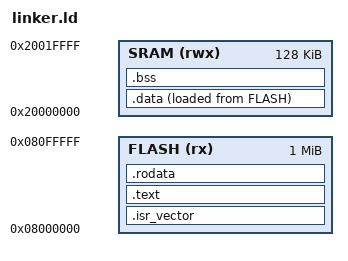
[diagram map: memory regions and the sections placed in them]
/* Linker script for STM32F407VG */
/* 1 MB Flash, 192 KB SRAM (128K main + 64K CCM) */

MEMORY
{
    FLASH (rx)  : ORIGIN = 0x08000000, LENGTH = 1024K
    SRAM  (rwx) : ORIGIN = 0x20000000, LENGTH = 128K
}

_stack_top = ORIGIN(SRAM) + LENGTH(SRAM);

SECTIONS
{
    .isr_vector :
    {
        . = ALIGN(4);
        KEEP(*(.isr_vector))
        . = ALIGN(4);
    } > FLASH

    .text :
    {
        . = ALIGN(4);
        *(.text)
        *(.text*)
        . = ALIGN(4);
    } > FLASH

    .rodata :
    {
        . = ALIGN(4);
        *(.rodata)
        *(.rodata*)
        . = ALIGN(4);
    } > FLASH

    _sidata = LOADADDR(.data);

    .data :
    {
        . = ALIGN(4);
        _sdata = .;
        *(.data)
        *(.data*)
        . = ALIGN(4);
        _edata = .;
    } > SRAM AT> FLASH

    .bss :
    {
        . = ALIGN(4);
        _sbss = .;
        *(.bss)
        *(.bss*)
        *(COMMON)
        . = ALIGN(4);
        _ebss = .;
    } > SRAM
}
